VERSION ""

NS_ :

BS_:

BU_: Vector__XXX ECU1

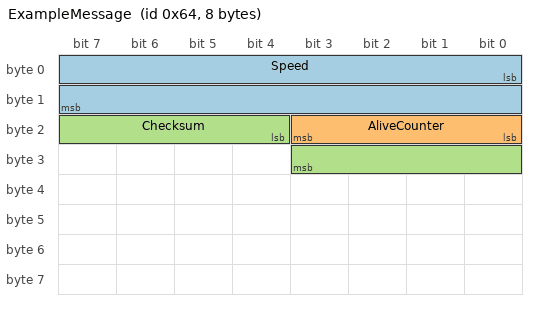
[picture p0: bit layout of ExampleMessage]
BO_ 100 ExampleMessage: 8 ECU1
 SG_ Speed : 0|16@1+ (0.01,0) [0|250] "km/h" Vector__XXX
 SG_ AliveCounter : 16|4@1+ (1,0) [0|15] "" Vector__XXX
 SG_ Checksum : 20|8@1+ (1,0) [0|255] "" Vector__XXX

CM_ SG_ 100 Speed "Vehicle speed (physical)";
VAL_ 100 AliveCounter 0 "A" 1 "B" 2 "C" 3 "D" ;
